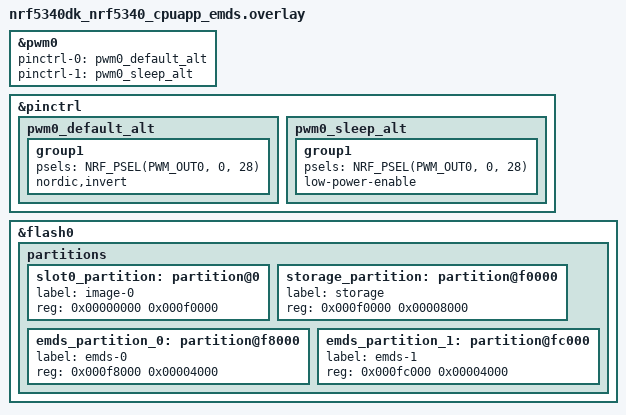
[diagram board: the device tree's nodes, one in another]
/*
 * Copyright (c) 2026 Nordic Semiconductor ASA
 *
 * SPDX-License-Identifier: LicenseRef-Nordic-5-Clause
 */

&pwm0 {
	status = "okay";
	pinctrl-0 = <&pwm0_default_alt>;
	pinctrl-1 = <&pwm0_sleep_alt>;
	pinctrl-names = "default", "sleep";
};

&pinctrl {
	pwm0_default_alt: pwm0_default_alt {
		group1 {
			psels = <NRF_PSEL(PWM_OUT0, 0, 28)>;
			nordic,invert;
		};
	};

	pwm0_sleep_alt: pwm0_sleep_alt {
		group1 {
			psels = <NRF_PSEL(PWM_OUT0, 0, 28)>;
			low-power-enable;
		};
	};
};

/delete-node/ &boot_partition;
/delete-node/ &slot0_partition;
/delete-node/ &slot1_partition;
/delete-node/ &storage_partition;

&flash0 {
	partitions {
		slot0_partition: partition@0 {
			label = "image-0";
			reg = <0x00000000 0x000f0000>;
		};

		storage_partition: partition@f0000 {
			label = "storage";
			reg = <0x000f0000 0x00008000>;
		};

		emds_partition_0: partition@f8000 {
			label = "emds-0";
			reg = <0x000f8000 0x00004000>;
		};

		emds_partition_1: partition@fc000 {
			label = "emds-1";
			reg = <0x000fc000 0x00004000>;
		};
	};
};
